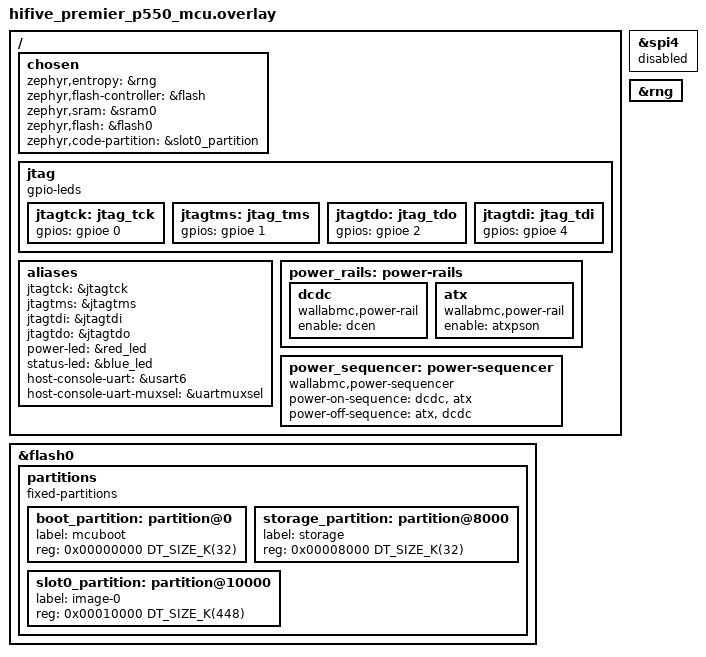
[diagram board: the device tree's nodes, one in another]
// hifive premier p550 mcu
/ {
    chosen {
        zephyr,entropy = &rng;
        zephyr,flash-controller = &flash;
        zephyr,sram = &sram0;
        zephyr,flash = &flash0;
        zephyr,code-partition = &slot0_partition;
    };

    jtag {
        // What is a better setting for this?
        compatible = "gpio-leds";

        // not connected for now
        jtagtck: jtag_tck {
            gpios = <&gpioe  0 GPIO_ACTIVE_HIGH>;
        };
        jtagtms: jtag_tms {
            gpios = <&gpioe  1 GPIO_ACTIVE_HIGH>;
        };
        jtagtdo: jtag_tdo {
            gpios = <&gpioe  2     GPIO_PULL_UP>;
        };
        jtagtdi: jtag_tdi {
            gpios = <&gpioe  4 GPIO_ACTIVE_HIGH>;
        };
    };

    aliases {
        jtagtck = &jtagtck;
        jtagtms = &jtagtms;
        jtagtdi = &jtagtdi;
        jtagtdo = &jtagtdo;

        power-led = &red_led;
        status-led = &blue_led;

	host-console-uart = &usart6;
	host-console-uart-muxsel = &uartmuxsel;
    };

    power_rails: power-rails {
        // Main DC-DC converters (5V/3.3V carrier, 5V SOM/SYS)
        dcdc: dcdc {
            compatible = "wallabmc,power-rail";
            enable = <&dcen>;
        };
        // ATX PSU main outputs
        atx: atx {
            compatible = "wallabmc,power-rail";
            enable = <&atxpson>;
        };
    };

    power_sequencer: power-sequencer {
        compatible = "wallabmc,power-sequencer";
        power-on-sequence = <&dcdc &atx>;
        power-off-sequence = <&atx &dcdc>;
    };
};

&spi4 {
     status = "disabled";
};

&rng {
    status = "okay";
};

&flash0 {
	partitions {
		compatible = "fixed-partitions";
		#address-cells = <1>;
		#size-cells = <1>;

		/* Sectors 0-1 (2*16 kbytes) for mcuboot */
                boot_partition: partition@0 {
                        label = "mcuboot";
                        reg = <0x00000000 DT_SIZE_K(32)>;
                };

		/* 2-3 (2*16 kbytes) for app storage, enough for NVS storage */
                storage_partition: partition@8000 {
                        label = "storage";
                        reg = <0x00008000 DT_SIZE_K(32)>;
                };

		/* 4-7 (64 + 3*128 kbytes) are for the application image */
                slot0_partition: partition@10000 {
                        label = "image-0";
                        reg = <0x00010000 DT_SIZE_K(448)>;
                };
	};
};
